# MDR1206AFI register map
Vendor: Milandr; File version: 1.0
CPU: BM-310S0, little endian
Registers are 32-bit, read-write, reset 0x0 unless marked. A register's access mark holds for its fields unless they carry their own. Offsets are from the block's base; [hi:lo] are bit positions; {n}, {i} and the like mark numbered series.

## ADCUI — ADCUI description
Base 0x50068000
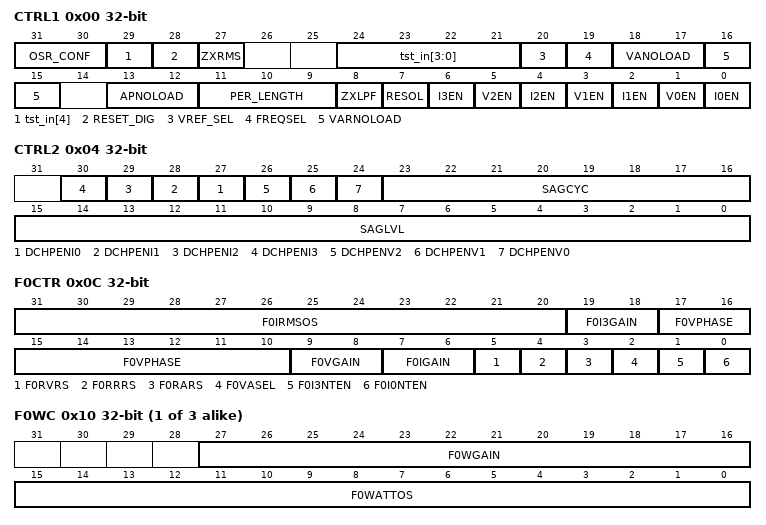
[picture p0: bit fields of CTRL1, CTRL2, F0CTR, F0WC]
0x00 CTRL1 — CTRL1 description
  [31:30] OSR_CONF — OSR_CONF description
  [29] tst_in[4] — tst_in[4] description
  [28] RESET_DIG — RESET_DIG description
  [27] ZXRMS — ZXRMS description
  [24:21] tst_in[3:0] — tst_in[3:0] description
  [20] VREF_SEL — VREF_SEL description
  [19] FREQSEL — FREQSEL description
  [18:17] VANOLOAD — VANOLOAD description
  [16:15] VARNOLOAD — VARNOLOAD description
  [13:12] APNOLOAD — APNOLOAD description
  [11:9] PER_LENGTH — PER_LENGTH description
  [8] ZXLPF — ZXLPF description
  [7] RESOL — RESOL description
  [2n] I{n}EN (n=0..3) — I{n}EN description
  [5] V2EN — V2EN description
  [3] V1EN — V1EN description
  [1] V0EN — V0EN description
0x04 CTRL2 — CTRL2 description
  [n+27] DCHPENI{n} (n=0..3) — DCHPENI{n} description
  [26] DCHPENV2 — DCHPENV2 description
  [25] DCHPENV1 — DCHPENV1 description
  [24] DCHPENV0 — DCHPENV0 description
  [23:16] SAGCYC — SAGCYC description
  [15:0] SAGLVL — SAGLVL description
0x08 CTRL3 — CTRL3 description
  [11:0] ZXTOUT — ZXTOUT description
0x0C F0CTR — F0CTR description
  [31:20] F0IRMSOS — F0IRMSOS description
  [19:18] F0I3GAIN — F0I3GAIN description
  [17:10] F0VPHASE — F0VPHASE description
  [9:8] F0VGAIN — F0VGAIN description
  [7:6] F0IGAIN — F0IGAIN description
  [5] F0RVRS wo — F0RVRS description
  [4] F0RRRS wo — F0RRRS description
  [3] F0RARS wo — F0RARS description
  [2] F0VASEL — F0VASEL description
  [1] F0I3NTEN — F0I3NTEN description
  [0] F0I0NTEN — F0I0NTEN description
{0x10+0x58*i} F{i}WC (i=0..2) — F{i}WC description
  [27:16] F{i}WGAIN — F{i}WGAIN description
  [15:0] F{i}WATTOS — F{i}WATTOS description
{0x14+0x58*i} F{i}WATTP ro (i=0..2) — F{i}WATTP description
{0x18+0x58*i} F{i}WATTN ro (i=0..2) — F{i}WATTN description
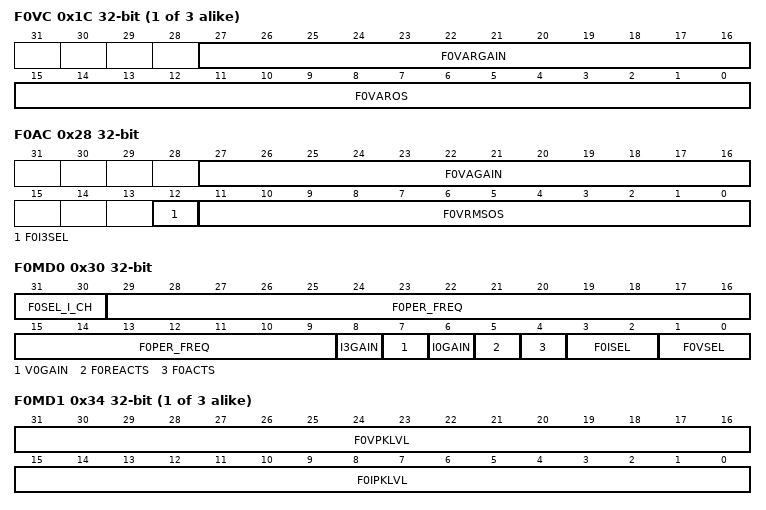
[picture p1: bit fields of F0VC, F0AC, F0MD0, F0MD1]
{0x1C+0x58*i} F{i}VC (i=0..2) — F{i}VC description
  [27:16] F{i}VARGAIN — F{i}VARGAIN description
  [15:0] F{i}VAROS — F{i}VAROS description
{0x20+0x58*i} F{i}VARP ro (i=0..2) — F{i}VARP description
{0x24+0x58*i} F{i}VARN ro (i=0..2) — F{i}VARN description
0x28 F0AC — F0AC description
  [27:16] F0VAGAIN — F0VAGAIN description
  [12] F0I3SEL — F0I3SEL description
  [11:0] F0VRMSOS — F0VRMSOS description
{0x2C+0x58*i} F{i}VR ro (i=0..2) — F{i}VR description
0x30 F0MD0 — F0MD0 description
  [31:30] F0SEL_I_CH — F0SEL_I_CH description
  [29:9] F0PER_FREQ ro — F0PER_FREQ description
  [8] I3GAIN — I3GAIN description
  [7] V0GAIN — V0GAIN description
  [6] I0GAIN — I0GAIN description
  [5] F0REACTS ro — F0REACTS description
  [4] F0ACTS ro — F0ACTS description
  [3:2] F0ISEL — F0ISEL description
  [1:0] F0VSEL — F0VSEL description
{0x34+0x58*i} F{i}MD1 (i=0..2) — F{i}MD1 description
  [31:16] F{i}VPKLVL — F{i}VPKLVL description
  [15:0] F{i}IPKLVL — F{i}IPKLVL description
0x38 F0VPEAK — F0VPEAK description
  [23:0] F0VPEAK
0x3C F0IPEAK — F0IPEAK description
  [23:0] F0IPEAK
0x40 F0VDAT — F0VDAT description
  [23:0] F0VDAT ro
0x44 F0I0DAT — F0I0DAT description
  [23:0] F0I0DAT ro
0x48 F0I3DAT — F0I3DAT description
  [23:0] F0I3DAT ro
0x4C F0VRMS — F0VRMS description
  [23:0] F0VRMS ro
{0x50+0x58*i} F{i}VRMS2 ro (i=0..2) — F{i}VRMS2 description
0x54 F0IRMS — F0IRMS description
  [23:0] F0IRMS ro
{0x58+0x58*i} F{i}IRMS2 ro (i=0..2) — F{i}IRMS2 description
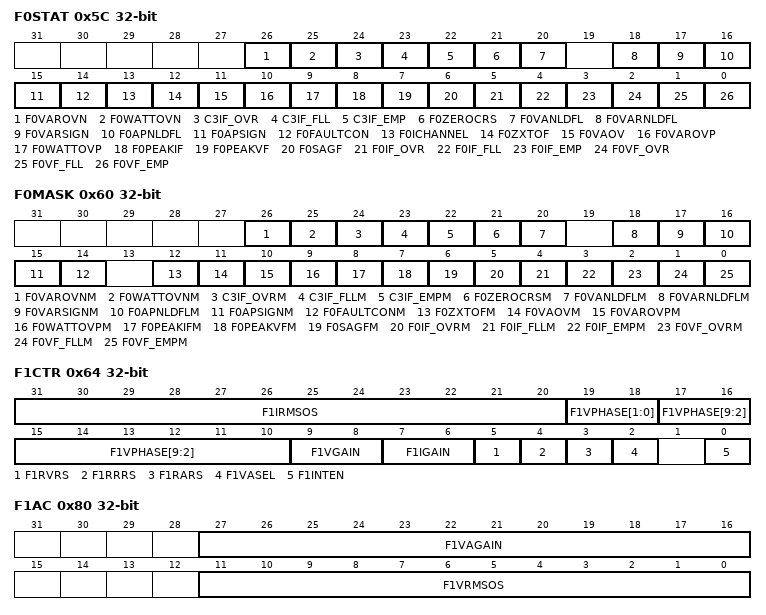
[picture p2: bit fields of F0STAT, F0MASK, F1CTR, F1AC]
0x5C F0STAT — F0STAT description
  [26] F0VAROVN — F0VAROVN description
  [25] F0WATTOVN — F0WATTOVN description
  [24] C3IF_OVR — C3IF_OVR description
  [23] C3IF_FLL ro — C3IF_FLL description
  [22] C3IF_EMP ro — C3IF_EMP description
  [21] F0ZEROCRS — F0ZEROCRS description
  [20] F0VANLDFL ro — F0VANLDFL description
  [18] F0VARNLDFL ro — F0VARNLDFL description
  [17] F0VARSIGN — F0VARSIGN description
  [16] F0APNLDFL ro — F0APNLDFL description
  [15] F0APSIGN — F0APSIGN description
  [14] F0FAULTCON — F0FAULTCON description
  [13] F0ICHANNEL ro — F0ICHANNEL description
  [12] F0ZXTOF — F0ZXTOF description
  [11] F0VAOV — F0VAOV description
  [10] F0VAROVP — F0VAROVP description
  [9] F0WATTOVP — F0WATTOVP description
  [8] F0PEAKIF — F0PEAKIF description
  [7] F0PEAKVF — F0PEAKVF description
  [6] F0SAGF — F0SAGF description
  [5] F0IF_OVR — F0IF_OVR description
  [4] F0IF_FLL ro — F0IF_FLL description
  [3] F0IF_EMP ro — F0IF_EMP description
  [2] F0VF_OVR — F0VF_OVR description
  [1] F0VF_FLL ro — F0VF_FLL description
  [0] F0VF_EMP ro — F0VF_EMP description
0x60 F0MASK — F0MASK description
  [26] F0VAROVNM — F0VAROVNM description
  [25] F0WATTOVNM — F0WATTOVNM description
  [24] C3IF_OVRM — C3IF_OVRM description
  [23] C3IF_FLLM — C3IF_FLLM description
  [22] C3IF_EMPM — C3IF_EMPM description
  [21] F0ZEROCRSM — F0ZEROCRSM description
  [20] F0VANLDFLM — F0VANLDFLM description
  [18] F0VARNLDFLM — F0VARNLDFLM description
  [17] F0VARSIGNM — F0VARSIGNM description
  [16] F0APNLDFLM — F0APNLDFLM description
  [15] F0APSIGNM — F0APSIGNM description
  [14] F0FAULTCONM — F0FAULTCONM description
  [12] F0ZXTOFM — F0ZXTOFM description
  [11] F0VAOVM — F0VAOVM description
  [10] F0VAROVPM — F0VAROVPM description
  [9] F0WATTOVPM — F0WATTOVPM description
  [8] F0PEAKIFM — F0PEAKIFM description
  [7] F0PEAKVFM — F0PEAKVFM description
  [6] F0SAGFM — F0SAGFM description
  [5] F0IF_OVRM — F0IF_OVRM description
  [4] F0IF_FLLM ro — F0IF_FLLM description
  [3] F0IF_EMPM ro — F0IF_EMPM description
  [2] F0VF_OVRM — F0VF_OVRM description
  [1] F0VF_FLLM ro — F0VF_FLLM description
  [0] F0VF_EMPM ro — F0VF_EMPM description
0x64 F1CTR — F1CTR description
  [31:20] F1IRMSOS — F1IRMSOS description
  [19:18] F1VPHASE[1:0] — F1VPHASE[1:0] description
  [17:10] F1VPHASE[9:2] — F1VPHASE[9:2] description
  [9:8] F1VGAIN — F1VGAIN description
  [7:6] F1IGAIN — F1IGAIN description
  [5] F1RVRS wo — F1RVRS description
  [4] F1RRRS wo — F1RRRS description
  [3] F1RARS wo — F1RARS description
  [2] F1VASEL — F1VASEL description
  [0] F1INTEN — F1INTEN description
0x80 F1AC — F1AC description
  [27:16] F1VAGAIN — F1VAGAIN description
  [11:0] F1VRMSOS — F1VRMSOS description
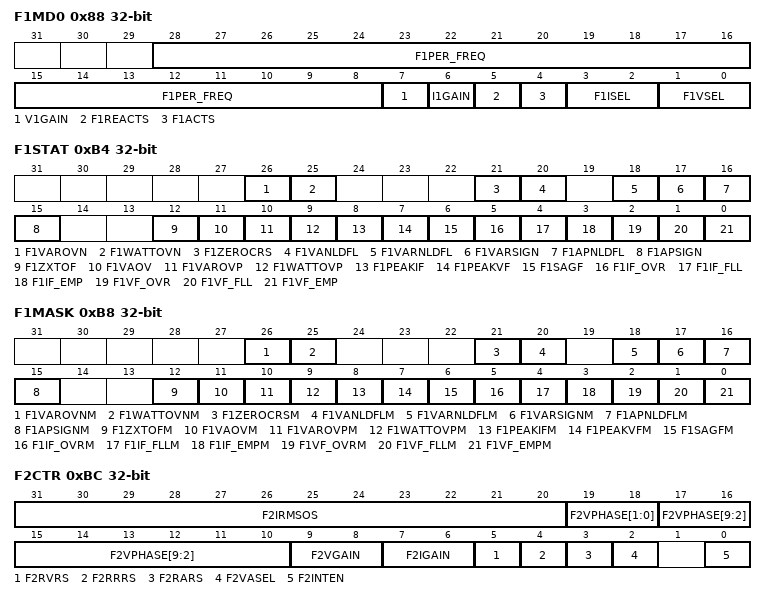
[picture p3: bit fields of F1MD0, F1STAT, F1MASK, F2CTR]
0x88 F1MD0 — F1MD0 description
  [28:8] F1PER_FREQ ro — F1PER_FREQ description
  [7] V1GAIN — V1GAIN description
  [6] I1GAIN — I1GAIN description
  [5] F1REACTS ro — F1REACTS description
  [4] F1ACTS ro — F1ACTS description
  [3:2] F1ISEL — F1ISEL description
  [1:0] F1VSEL — F1VSEL description
0x90 F1MD2 — F1MD2 description
  [16:0] F1PHASE ro — F1PHASE description
0x94 F1VPEAK — F1VPEAK description
  [23:0] F1VPEAK
0x98 F1IPEAK — F1IPEAK description
  [23:0] F1IPEAK
0x9C F1VDAT — F1VDAT description
  [23:0] F1VDAT ro
0xA0 F1IDAT — F1IDAT description
  [23:0] F1IDAT ro
0xA4 F1VRMS — F1VRMS description
  [23:0] F1VRMS ro
0xAC F1IRMS — F1IRMS description
  [23:0] F1IRMS
0xB4 F1STAT — F1STAT description
  [26] F1VAROVN — F1VAROVN description
  [25] F1WATTOVN — F1WATTOVN description
  [21] F1ZEROCRS — F1ZEROCRS description
  [20] F1VANLDFL ro — F1VANLDFL description
  [18] F1VARNLDFL ro — F1VARNLDFL description
  [17] F1VARSIGN — F1VARSIGN description
  [16] F1APNLDFL ro — F1APNLDFL description
  [15] F1APSIGN — F1APSIGN description
  [12] F1ZXTOF — F1ZXTOF description
  [11] F1VAOV — F1VAOV description
  [10] F1VAROVP — F1VAROVP description
  [9] F1WATTOVP — F1WATTOVP description
  [8] F1PEAKIF — F1PEAKIF description
  [7] F1PEAKVF — F1PEAKVF description
  [6] F1SAGF — F1SAGF description
  [5] F1IF_OVR — F1IF_OVR description
  [4] F1IF_FLL ro — F1IF_FLL description
  [3] F1IF_EMP ro — F1IF_EMP description
  [2] F1VF_OVR — F1VF_OVR description
  [1] F1VF_FLL ro — F1VF_FLL description
  [0] F1VF_EMP ro — F1VF_EMP description
0xB8 F1MASK — F1MASK description
  [26] F1VAROVNM — F1VAROVNM description
  [25] F1WATTOVNM — F1WATTOVNM description
  [21] F1ZEROCRSM — F1ZEROCRSM description
  [20] F1VANLDFLM — F1VANLDFLM description
  [18] F1VARNLDFLM — F1VARNLDFLM description
  [17] F1VARSIGNM — F1VARSIGNM description
  [16] F1APNLDFLM — F1APNLDFLM description
  [15] F1APSIGNM — F1APSIGNM description
  [12] F1ZXTOFM — F1ZXTOFM description
  [11] F1VAOVM — F1VAOVM description
  [10] F1VAROVPM — F1VAROVPM description
  [9] F1WATTOVPM — F1WATTOVPM description
  [8] F1PEAKIFM — F1PEAKIFM description
  [7] F1PEAKVFM — F1PEAKVFM description
  [6] F1SAGFM — F1SAGFM description
  [5] F1IF_OVRM — F1IF_OVRM description
  [4] F1IF_FLLM — F1IF_FLLM description
  [3] F1IF_EMPM — F1IF_EMPM description
  [2] F1VF_OVRM — F1VF_OVRM description
  [1] F1VF_FLLM — F1VF_FLLM description
  [0] F1VF_EMPM — F1VF_EMPM description
0xBC F2CTR — F2CTR description
  [31:20] F2IRMSOS — F2IRMSOS description
  [19:18] F2VPHASE[1:0] — F2VPHASE[1:0] description
  [17:10] F2VPHASE[9:2] — F2VPHASE[9:2] description
  [9:8] F2VGAIN — F2VGAIN description
  [7:6] F2IGAIN — F2IGAIN description
  [5] F2RVRS wo — F2RVRS description
  [4] F2RRRS wo — F2RRRS description
  [3] F2RARS wo — F2RARS description
  [2] F2VASEL — F2VASEL description
  [0] F2INTEN — F2INTEN description
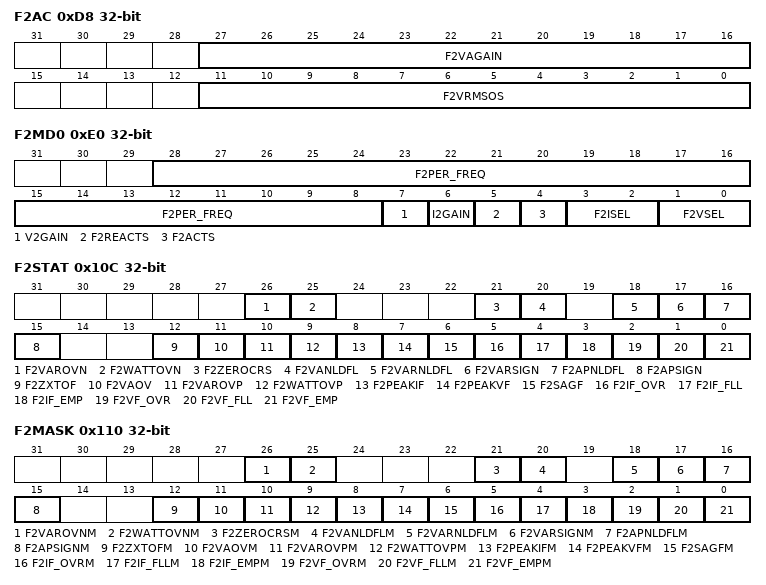
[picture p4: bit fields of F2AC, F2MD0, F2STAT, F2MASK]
0xD8 F2AC — F2AC description
  [27:16] F2VAGAIN — F2VAGAIN description
  [11:0] F2VRMSOS — F2VRMSOS description
0xE0 F2MD0 — F2MD0 description
  [28:8] F2PER_FREQ ro — F2PER_FREQ description
  [7] V2GAIN — V2GAIN description
  [6] I2GAIN — I2GAIN description
  [5] F2REACTS ro — F2REACTS description
  [4] F2ACTS ro — F2ACTS description
  [3:2] F2ISEL — F2ISEL description
  [1:0] F2VSEL — F2VSEL description
0xE8 F2MD2 — F2MD2 description
  [16:0] F2PHASE — F2PHASE description
0xEC F2VPEAK — F2VPEAK description
  [23:0] F2VPEAK
0xF0 F2IPEAK — F2IPEAK description
  [23:0] F2IPEAK
0xF4 F2VDAT — F2VDAT description
  [23:0] F2VDAT
0xF8 F2IDAT — F2IDAT description
  [23:0] F2IDAT
0xFC F2VRMS — F2VRMS description
  [23:0] F2VRMS
0x104 F2IRMS — F2IRMS description
  [23:0] F2IRMS
0x10C F2STAT — F2STAT description
  [26] F2VAROVN — F2VAROVN description
  [25] F2WATTOVN — F2WATTOVN description
  [21] F2ZEROCRS — F2ZEROCRS description
  [20] F2VANLDFL ro — F2VANLDFL description
  [18] F2VARNLDFL ro — F2VARNLDFL description
  [17] F2VARSIGN — F2VARSIGN description
  [16] F2APNLDFL ro — F2APNLDFL description
  [15] F2APSIGN — F2APSIGN description
  [12] F2ZXTOF — F2ZXTOF description
  [11] F2VAOV — F2VAOV description
  [10] F2VAROVP — F2VAROVP description
  [9] F2WATTOVP — F2WATTOVP description
  [8] F2PEAKIF — F2PEAKIF description
  [7] F2PEAKVF — F2PEAKVF description
  [6] F2SAGF — F2SAGF description
  [5] F2IF_OVR — F2IF_OVR description
  [4] F2IF_FLL ro — F2IF_FLL description
  [3] F2IF_EMP ro — F2IF_EMP description
  [2] F2VF_OVR — F2VF_OVR description
  [1] F2VF_FLL ro — F2VF_FLL description
  [0] F2VF_EMP ro — F2VF_EMP description
0x110 F2MASK — F2MASK description
  [26] F2VAROVNM — F2VAROVNM description
  [25] F2WATTOVNM — F2WATTOVNM description
  [21] F2ZEROCRSM — F2ZEROCRSM description
  [20] F2VANLDFLM — F2VANLDFLM description
  [18] F2VARNLDFLM — F2VARNLDFLM description
  [17] F2VARSIGNM — F2VARSIGNM description
  [16] F2APNLDFLM — F2APNLDFLM description
  [15] F2APSIGNM — F2APSIGNM description
  [12] F2ZXTOFM — F2ZXTOFM description
  [11] F2VAOVM — F2VAOVM description
  [10] F2VAROVPM — F2VAROVPM description
  [9] F2WATTOVPM — F2WATTOVPM description
  [8] F2PEAKIFM — F2PEAKIFM description
  [7] F2PEAKVFM — F2PEAKVFM description
  [6] F2SAGFM — F2SAGFM description
  [5] F2IF_OVRM — F2IF_OVRM description
  [4] F2IF_FLLM — F2IF_FLLM description
  [3] F2IF_EMPM — F2IF_EMPM description
  [2] F2VF_OVRM — F2VF_OVRM description
  [1] F2VF_FLLM — F2VF_FLLM description
  [0] F2VF_EMPM — F2VF_EMPM description
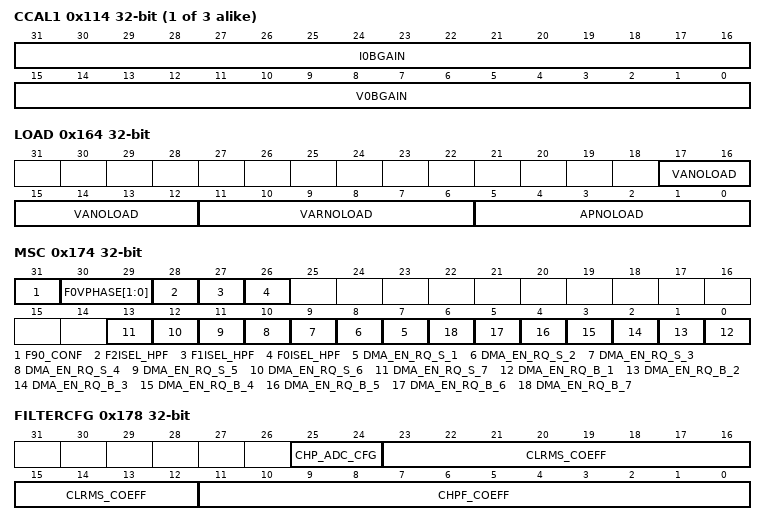
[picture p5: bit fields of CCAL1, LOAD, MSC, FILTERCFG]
{0x110+4i} CCAL{i} (i=1..3) — CCAL{i} description
  [31:16] I{i-1}BGAIN — I{i-1}BGAIN description
  [15:0] V{i-1}BGAIN — V{i-1}BGAIN description
0x120 CCAL4 — CCAL4 description
  [15:0] I3BGAIN — I3BGAIN description
0x124 F0IRMS_INACTIVE — F0IRMS_INACTIVE description
  [23:0] F0IRMS_INACTIVE ro
{0x128+0x14*i} F{i}WATTP_L (i=0..2) — F{i}WATTP_L description
  [24:0] F{i}WATTHRP_L ro — F{i}WATTHRP_L description
{0x12C+0x14*i} F{i}WATTN_L (i=0..2) — F{i}WATTN_L description
  [24:0] F{i}WATTHRN_L ro — F{i}WATTHRN_L description
{0x130+0x14*i} F{i}VARP_L (i=0..2) — F{i}VARP_L description
  [24:0] F{i}VARHRP_L ro — F{i}VARHRP_L description
{0x134+0x14*i} F{i}VARN_L (i=0..2) — F{i}VARN_L description
  [24:0] F{i}VARHRN_L ro — F{i}VARHRN_L description
{0x138+0x14*i} F{i}VR_L (i=0..2) — F{i}VR_L description
  [24:0] F{i}VAHR_L ro — F{i}VAHR_L description
0x164 LOAD — LOAD description
  [17:12] VANOLOAD — VANOLOAD description
  [11:6] VARNOLOAD — VARNOLOAD description
  [5:0] APNOLOAD — APNOLOAD description
{0x168+4i} F{i}VRMS_TRUE (i=0..2) — F{i}VRMS_TRUE description
  [28:0] F{i}VRMS_TRUE
0x174 MSC — MSC description
  [31] F90_CONF — F90_CONF description
  [30:29] F0VPHASE[1:0] — F0VPHASE[1:0] description
  [28] F2ISEL_HPF — F2ISEL_HPF description
  [27] F1ISEL_HPF — F1ISEL_HPF description
  [26] F0ISEL_HPF — F0ISEL_HPF description
  [n+6] DMA_EN_RQ_S_{n} (n=1..7) — DMA_EN_RQ_S_{n} description
  [n-1] DMA_EN_RQ_B_{n} (n=1..7) — DMA_EN_RQ_B_{n} description
0x178 FILTERCFG — FILTERCFG description
  [25:24] CHP_ADC_CFG — CHP_ADC_CFG description
  [23:12] CLRMS_COEFF — CLRMS_COEFF description
  [11:0] CHPF_COEFF — CHPF_COEFF description
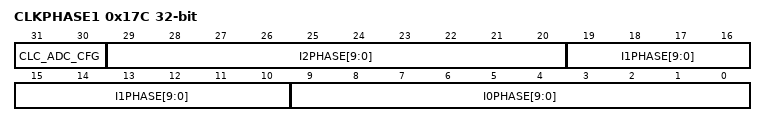
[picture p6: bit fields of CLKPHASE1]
0x17C CLKPHASE1 — CLKPHASE1 description
  [31:30] CLC_ADC_CFG — CLC_ADC_CFG description
  [29:20] I2PHASE[9:0] — I2PHASE[9:0] description
  [19:10] I1PHASE[9:0] — I1PHASE[9:0] description
  [9:0] I0PHASE[9:0] — I0PHASE[9:0] description
0x180 CLKPHASE2 — CLKPHASE2 description
  [9:0] I3PHASE[9:0] — I3PHASE[9:0] description
